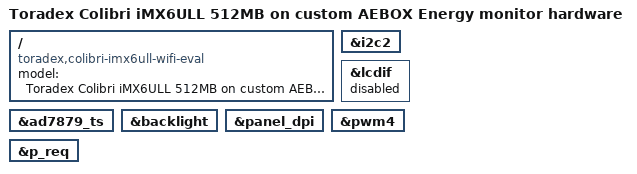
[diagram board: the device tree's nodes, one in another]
// SPDX-License-Identifier: GPL-2.0-or-later OR MIT
/*
 * Copyright 2022-2024 AEBOX 
 */

/dts-v1/;

#include "imx6ull-colibri-wifi.dtsi"
#include "imx6ull-colibri-eval-v3.dtsi"

/ {
        model = "Toradex Colibri iMX6ULL 512MB on custom AEBOX Energy monitor hardware";
        compatible = "toradex,colibri-imx6ull-wifi-eval", "fsl,imx6ull";
};

&ad7879_ts {
        status = "okay";
};

&backlight {
        status = "okay";
};

&i2c2 {
        status = "okay";
};

&lcdif {
        status = "disabled";
};

&panel_dpi {
        status = "okay";
};

&pwm4 {
        status = "okay";
};

&p_req {
	status = "okay";
};
